# SPI1 register map
Registers from a debugger description file.
Registers are 32-bit, access not given, no defined reset value unless marked. A register's access mark holds for its fields unless they carry their own. Addresses are absolute; registers are grouped by the start of their names; lines under a group give offsets from that group; [hi:lo] are bit positions; {n}, {i} and the like mark numbered series; 'fields as' and 'values as' point back to an identical list; <NAME> marks a mode.

## SPI1
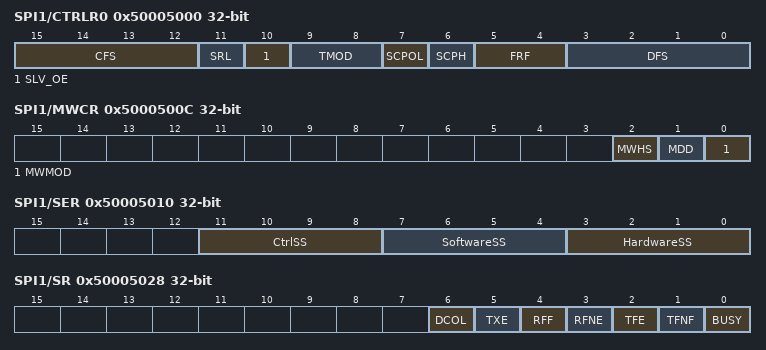
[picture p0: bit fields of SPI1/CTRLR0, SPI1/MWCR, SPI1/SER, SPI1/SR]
0x50005000 SPI1/CTRLR0
  [15:12] CFS, [11] SRL, [10] SLV_OE, [9:8] TMOD, [7] SCPOL, [6] SCPH, [5:4] FRF, [3:0] DFS
0x50005004 SPI1/CTRLR1
  [15:0] NDF
0x50005008 SPI1/SSIENR
  [0] SSIENR
0x5000500C SPI1/MWCR
  [2] MWHS, [1] MDD, [0] MWMOD
0x50005010 SPI1/SER
  [11:8] CtrlSS, [7:4] SoftwareSS, [3:0] HardwareSS
0x50005014 SPI1/BAUDR
  [15:0] SCKDV
0x50005018 SPI1/TXFTLR
  [3:0] TFT
0x5000501C SPI1/RXFTLR
  [3:0] RFT
0x50005020 SPI1/TXFLR ro
  [3:0] TXTFL
0x50005024 SPI1/RXFLR ro
  [3:0] RXTFL
0x50005028 SPI1/SR ro
  [6] DCOL, [5] TXE, [4] RFF, [3] RFNE, [2] TFE, [1] TFNF, [0] BUSY
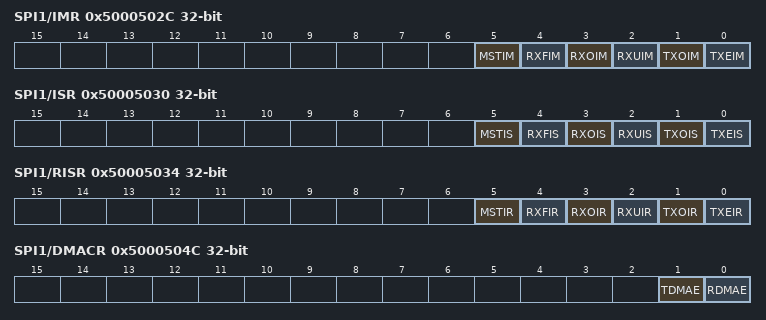
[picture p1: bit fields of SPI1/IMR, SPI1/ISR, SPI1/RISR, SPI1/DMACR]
0x5000502C SPI1/IMR
  [5] MSTIM, [4] RXFIM, [3] RXOIM, [2] RXUIM, [1] TXOIM, [0] TXEIM
0x50005030 SPI1/ISR ro
  [5] MSTIS, [4] RXFIS, [3] RXOIS, [2] RXUIS, [1] TXOIS, [0] TXEIS
0x50005034 SPI1/RISR ro
  [5] MSTIR, [4] RXFIR, [3] RXOIR, [2] RXUIR, [1] TXOIR, [0] TXEIR
0x50005038 SPI1/TXOICR ro
  [0] TXOICR
0x5000503C SPI1/RXOICR ro
  [0] RXOICR
0x50005040 SPI1/RXUICR ro
  [0] RXUICR
0x50005044 SPI1/MSTICR ro
  [0] MSTICR
0x50005048 SPI1/ICR ro
  [0] ICR
0x5000504C SPI1/DMACR
  [1] TDMAE, [0] RDMAE
0x50005050 SPI1/DMATDLR
  [3:0] DMATDLR
0x50005054 SPI1/DMARDLR
  [3:0] DMARDLR
0x50005058 SPI1/IDR ro
  [31:0] ICR
0x5000505C SPI1/SSI_COMP_VERSION ro
0x50005060 SPI1/DR
  [15:0] DR
0x500050F0 SPI1/RX_SAMPLE_DLY
  [7:0] RX_Sample_Delay
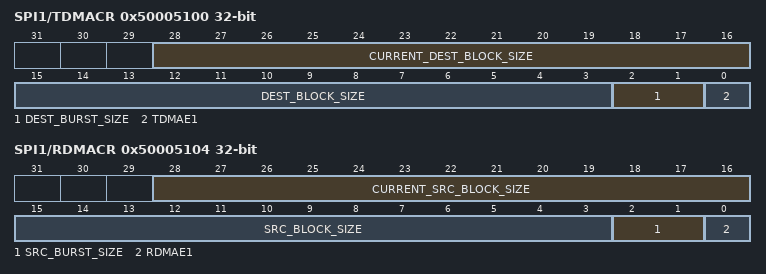
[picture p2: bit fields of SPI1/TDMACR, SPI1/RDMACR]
0x50005100 SPI1/TDMACR
  [28:16] CURRENT_DEST_BLOCK_SIZE, [15:3] DEST_BLOCK_SIZE, [2:1] DEST_BURST_SIZE, [0] TDMAE1
0x50005104 SPI1/RDMACR
  [28:16] CURRENT_SRC_BLOCK_SIZE, [15:3] SRC_BLOCK_SIZE, [2:1] SRC_BURST_SIZE, [0] RDMAE1
